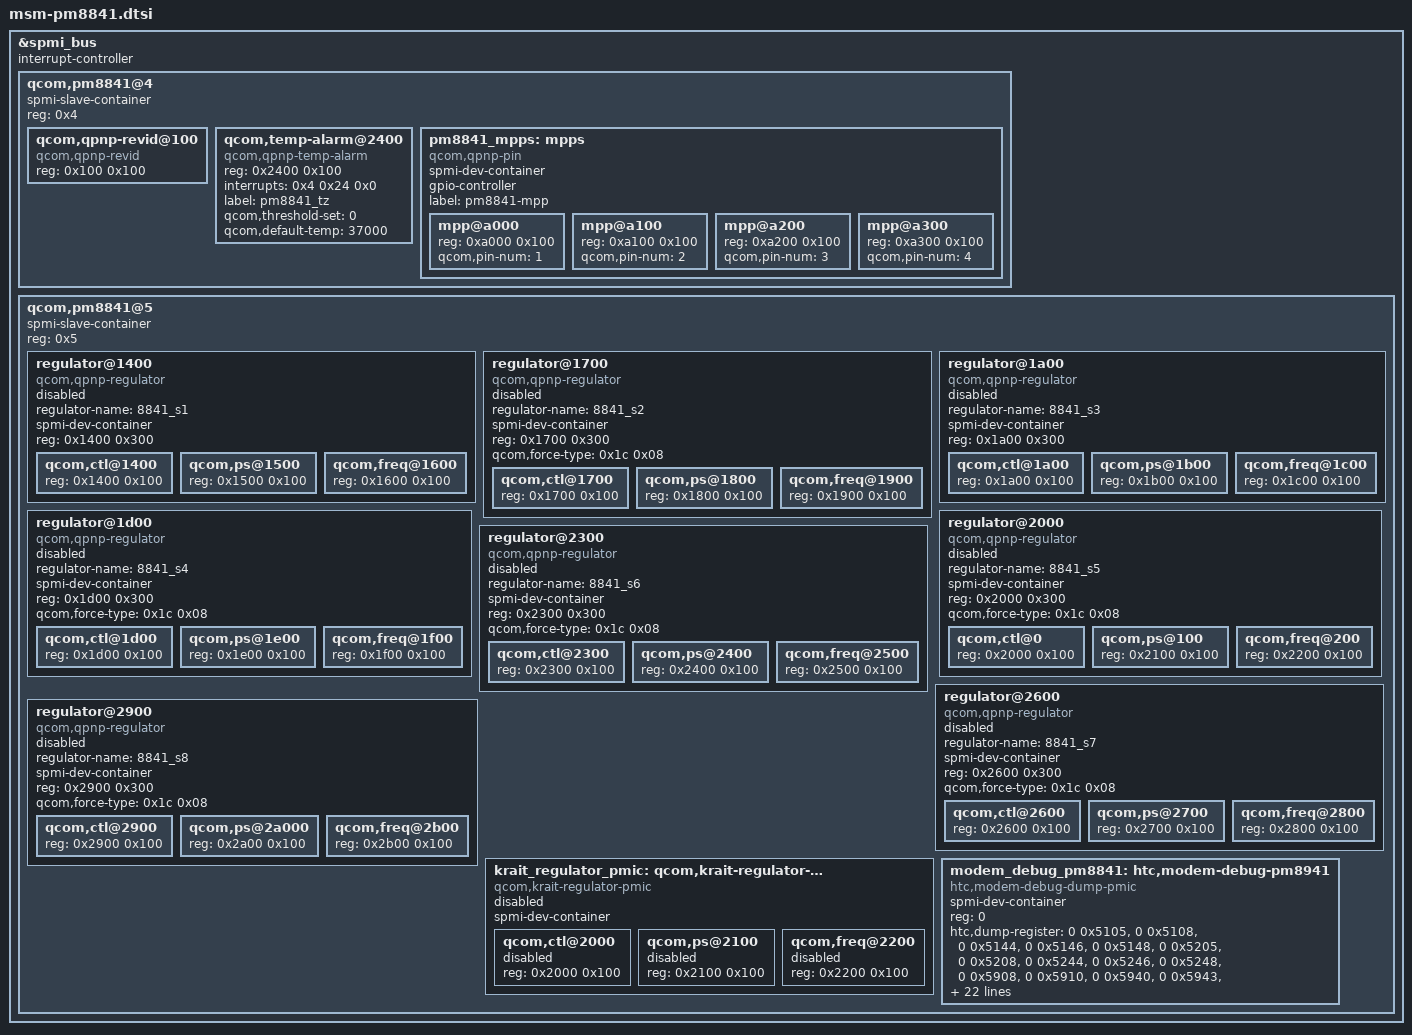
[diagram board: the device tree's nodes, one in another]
/* Copyright (c) 2012-2013, The Linux Foundation. All rights reserved.
 *
 * This program is free software; you can redistribute it and/or modify
 * it under the terms of the GNU General Public License version 2 and
 * only version 2 as published by the Free Software Foundation.
 *
 * This program is distributed in the hope that it will be useful,
 * but WITHOUT ANY WARRANTY; without even the implied warranty of
 * MERCHANTABILITY or FITNESS FOR A PARTICULAR PURPOSE.  See the
 * GNU General Public License for more details.
 */

&spmi_bus {
	#address-cells = <1>;
	#size-cells = <0>;
	interrupt-controller;
	#interrupt-cells = <3>;

	qcom,pm8841@4 {
		spmi-slave-container;
		reg = <0x4>;
		#address-cells = <1>;
		#size-cells = <1>;

		qcom,qpnp-revid@100 {
			compatible = "qcom,qpnp-revid";
			reg = <0x100 0x100>;
		};

		qcom,temp-alarm@2400 {
			compatible = "qcom,qpnp-temp-alarm";
			reg = <0x2400 0x100>;
			interrupts = <0x4 0x24 0x0>;
			label = "pm8841_tz";
			qcom,threshold-set = <0>;
			qcom,default-temp = <37000>;
		};

		pm8841_mpps: mpps {
			spmi-dev-container;
			compatible = "qcom,qpnp-pin";
			gpio-controller;
			#gpio-cells = <2>;
			#address-cells = <1>;
			#size-cells = <1>;
			label = "pm8841-mpp";

			mpp@a000 {
				reg = <0xa000 0x100>;
				qcom,pin-num = <1>;
			};

			mpp@a100 {
				reg = <0xa100 0x100>;
				qcom,pin-num = <2>;
			};

			mpp@a200 {
				reg = <0xa200 0x100>;
				qcom,pin-num = <3>;
			};

			mpp@a300 {
				reg = <0xa300 0x100>;
				qcom,pin-num = <4>;
			};
		};
	};

	qcom,pm8841@5 {
		spmi-slave-container;
		reg = <0x5>;
		#address-cells = <1>;
		#size-cells = <1>;

		regulator@1400 {
			regulator-name = "8841_s1";
			spmi-dev-container;
			#address-cells = <1>;
			#size-cells = <1>;
			compatible = "qcom,qpnp-regulator";
			reg = <0x1400 0x300>;
			status = "disabled";

			qcom,ctl@1400 {
				reg = <0x1400 0x100>;
			};
			qcom,ps@1500 {
				reg = <0x1500 0x100>;
			};
			qcom,freq@1600 {
				reg = <0x1600 0x100>;
			};
		};

		regulator@1700 {
			regulator-name = "8841_s2";
			spmi-dev-container;
			#address-cells = <1>;
			#size-cells = <1>;
			compatible = "qcom,qpnp-regulator";
			reg = <0x1700 0x300>;
			status = "disabled";
			qcom,force-type = <0x1c 0x08>;

			qcom,ctl@1700 {
				reg = <0x1700 0x100>;
			};
			qcom,ps@1800 {
				reg = <0x1800 0x100>;
			};
			qcom,freq@1900 {
				reg = <0x1900 0x100>;
			};
		};

		regulator@1a00 {
			regulator-name = "8841_s3";
			spmi-dev-container;
			#address-cells = <1>;
			#size-cells = <1>;
			compatible = "qcom,qpnp-regulator";
			reg = <0x1a00 0x300>;
			status = "disabled";

			qcom,ctl@1a00 {
				reg = <0x1a00 0x100>;
			};
			qcom,ps@1b00 {
				reg = <0x1b00 0x100>;
			};
			qcom,freq@1c00 {
				reg = <0x1c00 0x100>;
			};
		};

		regulator@1d00 {
			regulator-name = "8841_s4";
			spmi-dev-container;
			#address-cells = <1>;
			#size-cells = <1>;
			compatible = "qcom,qpnp-regulator";
			reg = <0x1d00 0x300>;
			status = "disabled";
			qcom,force-type = <0x1c 0x08>;

			qcom,ctl@1d00 {
				reg = <0x1d00 0x100>;
			};
			qcom,ps@1e00 {
				reg = <0x1e00 0x100>;
			};
			qcom,freq@1f00 {
				reg = <0x1f00 0x100>;
			};
		};

		regulator@2000 {
			regulator-name = "8841_s5";
			spmi-dev-container;
			#address-cells = <1>;
			#size-cells = <1>;
			compatible = "qcom,qpnp-regulator";
			reg = <0x2000 0x300>;
			status = "disabled";
			qcom,force-type = <0x1c 0x08>;

			qcom,ctl@0 {
				reg = <0x2000 0x100>;
			};
			qcom,ps@100 {
				reg = <0x2100 0x100>;
			};
			qcom,freq@200 {
				reg = <0x2200 0x100>;
			};
		};

		regulator@2300 {
			regulator-name = "8841_s6";
			spmi-dev-container;
			#address-cells = <1>;
			#size-cells = <1>;
			compatible = "qcom,qpnp-regulator";
			reg = <0x2300 0x300>;
			status = "disabled";
			qcom,force-type = <0x1c 0x08>;

			qcom,ctl@2300 {
				reg = <0x2300 0x100>;
			};
			qcom,ps@2400 {
				reg = <0x2400 0x100>;
			};
			qcom,freq@2500 {
				reg = <0x2500 0x100>;
			};
		};

		regulator@2600 {
			regulator-name = "8841_s7";
			spmi-dev-container;
			#address-cells = <1>;
			#size-cells = <1>;
			compatible = "qcom,qpnp-regulator";
			reg = <0x2600 0x300>;
			status = "disabled";
			qcom,force-type = <0x1c 0x08>;

			qcom,ctl@2600 {
				reg = <0x2600 0x100>;
			};
			qcom,ps@2700 {
				reg = <0x2700 0x100>;
			};
			qcom,freq@2800 {
				reg = <0x2800 0x100>;
			};
		};

		regulator@2900 {
			regulator-name = "8841_s8";
			spmi-dev-container;
			#address-cells = <1>;
			#size-cells = <1>;
			compatible = "qcom,qpnp-regulator";
			reg = <0x2900 0x300>;
			status = "disabled";
			qcom,force-type = <0x1c 0x08>;

			qcom,ctl@2900 {
				reg = <0x2900 0x100>;
			};
			qcom,ps@2a000 {
				reg = <0x2a00 0x100>;
			};
			qcom,freq@2b00 {
				reg = <0x2b00 0x100>;
			};
		};

		krait_regulator_pmic: qcom,krait-regulator-pmic@2000 {
			spmi-dev-container;
			compatible = "qcom,krait-regulator-pmic";
			#address-cells = <1>;
			#size-cells = <1>;
			status = "disabled";

			qcom,ctl@2000 {
				status = "disabled";
				reg = <0x2000 0x100>;
			};

			qcom,ps@2100 {
				status = "disabled";
				reg = <0x2100 0x100>;
			};

			qcom,freq@2200 {
				status = "disabled";
				reg = <0x2200 0x100>;
			};
		};

		modem_debug_pm8841: htc,modem-debug-pm8941 {
			spmi-dev-container;
			compatible = "htc,modem-debug-dump-pmic";
			#address-cells = <1>;
			#size-cells = <1>;
			reg = <0>;
			htc,dump-register =
			/* PM8941 BB_CLK1 */
			< 0 0x5105 >,
			< 0 0x5108 >,
			< 0 0x5144 >,
			< 0 0x5146 >,
			< 0 0x5148 >,
			/* PM8941 BB_CLK2 */
			< 0 0x5205 >,
			< 0 0x5208 >,
			< 0 0x5244 >,
			< 0 0x5246 >,
			< 0 0x5248 >,
			/* PM8941 CLK_DIST */
			< 0 0x5908 >,
			< 0 0x5910 >,
			< 0 0x5940 >,
			< 0 0x5943 >,
			< 0 0x5945 >,
			/* PM8941 SLEEP_CLK1 */
			< 0 0x5A10 >,
			< 0 0x5A44 >,
			< 0 0x5B05 >,
			/* PM8941 SMPS2 */
			< 1 0x1740 >,
			< 1 0x1741 >,
			< 1 0x1745 >,
			< 1 0x1746 >,
			< 1 0x1748 >,
			< 1 0x1950 >,
			< 1 0x184A >,
			< 1 0x184B >,
			< 1 0x184C >,
			/* PM8941 SMPS3 */
			< 1 0x1A40 >,
			< 1 0x1A41 >,
			< 1 0x1A45 >,
			< 1 0x1A46 >,
			< 1 0x1A48 >,
			< 1 0x1B4A >,
			< 1 0x1B4B >,
			/* PM8941 LDO1 */
			< 1 0x4040 >,
			< 1 0x4041 >,
			< 1 0x4045 >,
			< 1 0x4046 >,
			< 1 0x4048 >,
			< 1 0x404A >,
			/* PM8941 LDO6 & LDO7*/
			< 1 0x4508 >,
			< 1 0x4509 >,
			< 1 0x450A >,
			< 1 0x4540 >,
			< 1 0x4541 >,
			< 1 0x4545 >,
			< 1 0x4546 >,
			< 1 0x4548 >,
			< 1 0x454A >,
			< 1 0x4608 >,
			< 1 0x4640 >,
			< 1 0x4641 >,
			< 1 0x4645 >,
			< 1 0x4646 >,
			/* PM8841 SMPS1 */
			< 5 0x1408 >,
			< 5 0x1440 >,
			< 5 0x1441 >,
			< 5 0x1445 >,
			< 5 0x1446 >,
			< 5 0x1448 >,
			< 5 0x145B >,
			< 5 0x1646 >,
			/* PM8841 SMPS2  */
			< 5 0x1708 >,
			< 5 0x1709 >,
			< 5 0x170A >,
			< 5 0x170B >,
			< 5 0x1740 >,
			< 5 0x1741 >,
			< 5 0x1745 >,
			< 5 0x1746 >,
			< 5 0x1748 >,
			< 5 0x1760 >,
			< 5 0x1761 >,
			< 5 0x1840 >,
			< 5 0x1841 >,
			< 5 0x1851 >,
			< 5 0x1862 >,
			< 5 0x18C1 >,
			< 5 0x1946 >,
			/* PM8841 SMPS3  */
			< 5 0x1A08 >,
			< 5 0x1A40 >,
			< 5 0x1A44 >,
			< 5 0x1A41 >,
			< 5 0x1A45 >,
			< 5 0x1A46 >,
			< 5 0x1A48 >,
			< 5 0x1A60 >,
			< 5 0x1A61 >,
			< 5 0x1A62 >,
			< 5 0x1AF1 >,
			< 5 0x1AF2 >,
			< 5 0x1AF3 >,
			< 5 0x1B4A >,
			< 5 0x1B4B >,
			< 5 0x1B4C >,
			< 5 0x1BF1 >,
			< 5 0x1BF2 >,
			< 5 0x1C46 >,
			< 5 0x1C51 >;
		};
	};
};
